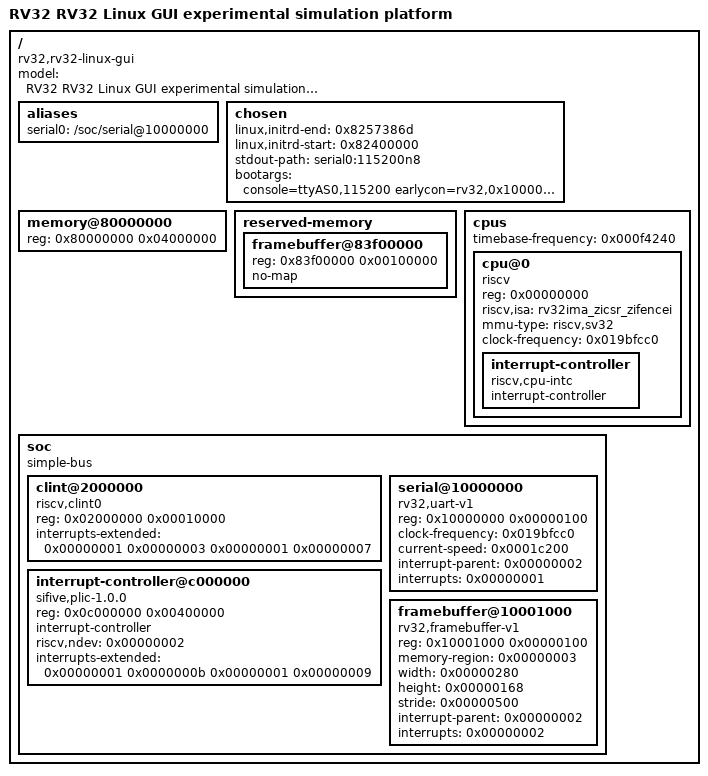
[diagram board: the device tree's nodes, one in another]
// 设备树描述固件传给 Linux 的硬件事实，属性不是运行时频率测量。
// software_current 中的 board27 源来自实际上传 DTB，CPU 和 UART 配置为 27 MHz。
// software_reference 中的旧 DTS 保留原貌，不作为本次实板的实际配置依据。
// memory 与 reserved-memory 的范围共同决定 Linux 可分配内存，不能只看 DDR 芯片总量。
/dts-v1/;

// Generated from the exact board27 DTB, not the legacy reference DTS.
// Source DTB SHA-256: d63d44fb79034a38faa5a58532e34731c89c47df2e2dc69345cc38fa88e47da1

/ {
    // compatible 匹配板级或外设驱动，字符串需要与内核驱动的 of match 表一致。
    compatible = "rv32,rv32-linux-gui";
    // model 保留原 DTB 的历史平台名称；其中 simulation 字样是字符串，不改变实板运行来源。
    model = "RV32 RV32 Linux GUI experimental simulation platform";
    // #address-cells 定义当前总线地址用几个 32 位单元表示，影响子节点 reg 的解释。
    #address-cells = <0x00000001>;
    // #size-cells 定义当前总线长度用几个 32 位单元表示，CPU 节点通常不声明地址长度。
    #size-cells = <0x00000001>;
    aliases {
        // serial0 给 stdout path 提供串口别名，实际节点仍由绝对路径指定。
        serial0 = "/soc/serial@10000000";
    };
    chosen {
        // linux,initrd-end 压缩 initramfs 结束地址，必须与实际上传文件的字节长度配套。
        linux,initrd-end = <0x8257386d>;
        // linux,initrd-start initramfs 起始物理地址，Linux 按此窗口找到根文件系统。
        linux,initrd-start = <0x82400000>;
        // stdout-path 固件推荐的串口输出目标及 115200 8N1 参数。
        stdout-path = "serial0:115200n8";
        // bootargs 指定 ttyAS0 earlycon 与 init 入口，这些参数决定真实内核日志的可见输出路径。
        bootargs = "console=ttyAS0,115200 earlycon=rv32,0x10000000 rdinit=/init loglevel=7";
    };
    memory@80000000 {
        device_type = "memory";
        // reg 原始单元为 0x80000000 0x04000000；按父节点的 address cells 与 size cells 分解地址及范围。
        reg = <0x80000000 0x04000000>;
    };
    reserved-memory {
        #address-cells = <0x00000001>;
        #size-cells = <0x00000001>;
        ranges;
        framebuffer@83f00000 {
            // reg 原始单元为 0x83f00000 0x00100000；按父节点的 address cells 与 size cells 分解地址及范围。
            reg = <0x83f00000 0x00100000>;
            // no-map 把保留区从 Linux 常规直接映射排除，但它本身不保证 DMA cache 一致性。
            no-map;
            // phandle 供其他节点引用的标识，只是设备树连接关系而非实际寄存器地址。
            phandle = <0x00000003>;
        };
    };
    cpus {
        #address-cells = <0x00000001>;
        #size-cells = <0x00000000>;
        // timebase-frequency mtime 的 1 MHz 计时基准，与 27 MHz CPU 配置值是不同概念。
        timebase-frequency = <0x000f4240>;
        cpu@0 {
            device_type = "cpu";
            // reg 原始单元为 0x00000000；按父节点的 address cells 与 size cells 分解地址及范围。
            reg = <0x00000000>;
            // status 决定内核是否启用该节点；实际上板 framebuffer 采用 okay，旧参考仍保留原状态。
            status = "okay";
            compatible = "riscv";
            // riscv,isa 向内核声明本平台 ISA 能力，实际行为仍需与 CPU RTL 支持相符。
            riscv,isa = "rv32ima_zicsr_zifencei";
            // mmu-type 声明 Sv32 虚拟内存模型，Linux 据此使用两级页表。
            mmu-type = "riscv,sv32";
            // clock-frequency 描述输入时钟配置值，不是运行过程中测量得到的频率。
            clock-frequency = <0x019bfcc0>;
            interrupt-controller {
                #interrupt-cells = <0x00000001>;
                interrupt-controller;
                compatible = "riscv,cpu-intc";
                phandle = <0x00000001>;
            };
        };
    };
    soc {
        compatible = "simple-bus";
        #address-cells = <0x00000001>;
        #size-cells = <0x00000001>;
        ranges;
        clint@2000000 {
            compatible = "riscv,clint0";
            // reg 原始单元为 0x02000000 0x00010000；按父节点的 address cells 与 size cells 分解地址及范围。
            reg = <0x02000000 0x00010000>;
            // interrupts-extended 成对列出目标中断控制器与中断号，把本地或外部中断接到正确上下文。
            interrupts-extended = <0x00000001 0x00000003 0x00000001 0x00000007>;
        };
        interrupt-controller@c000000 {
            compatible = "sifive,plic-1.0.0", "riscv,plic0";
            // reg 原始单元为 0x0c000000 0x00400000；按父节点的 address cells 与 size cells 分解地址及范围。
            reg = <0x0c000000 0x00400000>;
            #interrupt-cells = <0x00000001>;
            interrupt-controller;
            // riscv,ndev 声明 PLIC 的外部中断源数量，不等于 CPU hart 数。
            riscv,ndev = <0x00000002>;
            interrupts-extended = <0x00000001 0x0000000b 0x00000001 0x00000009>;
            phandle = <0x00000002>;
        };
        serial@10000000 {
            compatible = "rv32,uart-v1";
            // reg 原始单元为 0x10000000 0x00000100；按父节点的 address cells 与 size cells 分解地址及范围。
            reg = <0x10000000 0x00000100>;
            clock-frequency = <0x019bfcc0>;
            // current-speed 串口当前波特率 115200，必须与主机 8N1 配置相符。
            current-speed = <0x0001c200>;
            // interrupt-parent 引用中断所属控制器，引用号须和 phandle 对应。
            interrupt-parent = <0x00000002>;
            // interrupts 该设备的中断源编号，必须与 RTL 的 PLIC 接线对应。
            interrupts = <0x00000001>;
        };
        framebuffer@10001000 {
            compatible = "rv32,framebuffer-v1";
            // reg 原始单元为 0x10001000 0x00000100；按父节点的 address cells 与 size cells 分解地址及范围。
            reg = <0x10001000 0x00000100>;
            // memory-region 引用 framebuffer 专用保留显存，防止普通页面分配覆盖显示数据。
            memory-region = <0x00000003>;
            // width Linux fbdev ABI 的 640 像素页宽，ROI 缩小不改变这个值。
            width = <0x00000280>;
            // height Linux fbdev ABI 的 360 行页高，双缓冲第二页从另一个页高开始。
            height = <0x00000168>;
            // stride 每行字节跨度 1280，应用复制和硬件扫描均须沿用此跨度。
            stride = <0x00000500>;
            interrupt-parent = <0x00000002>;
            interrupts = <0x00000002>;
            status = "okay";
        };
    };
};
